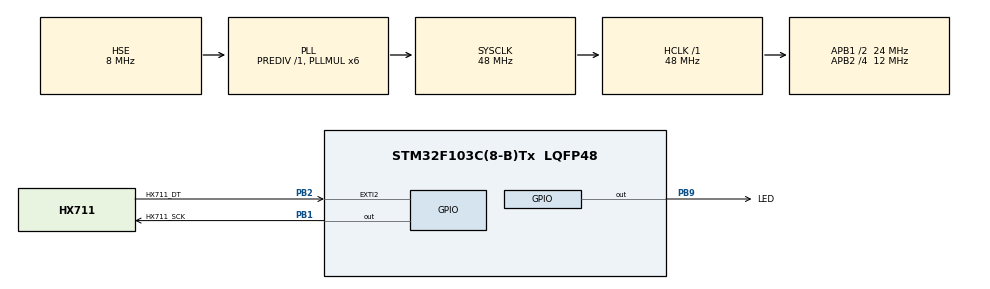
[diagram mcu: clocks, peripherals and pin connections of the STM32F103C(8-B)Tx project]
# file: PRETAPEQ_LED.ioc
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Mcu.Family=STM32F1
Mcu.Name=STM32F103C(8-B)Tx
Mcu.Package=LQFP48
NVIC.EXTI2_IRQn=true\:0\:0\:false\:false\:true\:true
NVIC.PriorityGroup=NVIC_PRIORITYGROUP_4
NVIC.TIM2_IRQn=true\:1\:0\:true\:false\:true\:true
PA13.Mode=Serial_Wire
PA13.Signal=SYS_JTMS-SWDIO
PA14.Mode=Serial_Wire
PA14.Signal=SYS_JTCK-SWCLK
PB1.GPIO_Label=HX711_SCK
PB1.GPIO_Speed=GPIO_SPEED_FREQ_HIGH
PB1.PinState=GPIO_PIN_SET
PB1.Signal=GPIO_Output
PB2.GPIO_Label=HX711_DT
PB2.GPIO_ModeDefaultEXTI=GPIO_MODE_IT_FALLING
PB2.GPIO_PuPd=GPIO_PULLDOWN
PB2.Signal=GPXTI2
PB9.GPIO_Label=LED
PB9.GPIO_Speed=GPIO_SPEED_FREQ_HIGH
PB9.PinState=GPIO_PIN_SET
PB9.Signal=GPIO_Output
PD0-OSC_IN.Mode=HSE-External-Oscillator
PD0-OSC_IN.Signal=RCC_OSC_IN
PD1-OSC_OUT.Mode=HSE-External-Oscillator
PD1-OSC_OUT.Signal=RCC_OSC_OUT
ProjectManager.HeapSize=0x200
ProjectManager.StackSize=0x400
ProjectManager.TargetToolchain=MDK-ARM V5
RCC.ADCPresc=RCC_ADCPCLK2_DIV6
RCC.AHBFreq_Value=48000000
RCC.APB1CLKDivider=RCC_HCLK_DIV2
RCC.APB1Freq_Value=24000000
RCC.APB1TimFreq_Value=48000000
RCC.APB2CLKDivider=RCC_HCLK_DIV4
RCC.APB2Freq_Value=12000000
RCC.APB2TimFreq_Value=24000000
RCC.HCLKFreq_Value=48000000
RCC.PLLMUL=RCC_PLL_MUL6
RCC.PLLSourceVirtual=RCC_PLLSOURCE_HSE
RCC.SYSCLKFreq_VALUE=48000000
RCC.SYSCLKSource=RCC_SYSCLKSOURCE_PLLCLK
RCC.USBFreq_Value=48000000
TIM2.Period=1000-1
TIM2.Prescaler=4800-1
VP_TIM2_VS_ClockSourceINT.Mode=Internal
board=custom

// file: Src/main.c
/**
  ******************************************************************************
  * @file           : main.c
  * @brief          : Main program body
  ******************************************************************************
  ** This notice applies to any and all portions of this file
  * that are not between comment pairs USER CODE BEGIN and
  * USER CODE END. Other portions of this file, whether
  * inserted by the user or by software development tools
  * are owned by their respective copyright owners.
  *
  * COPYRIGHT(c) 2019 STMicroelectronics
  *
  * Redistribution and use in source and binary forms, with or without modification,
  * are permitted provided that the following conditions are met:
  *   1. Redistributions of source code must retain the above copyright notice,
  *      this list of conditions and the following disclaimer.
  *   2. Redistributions in binary form must reproduce the above copyright notice,
  *      this list of conditions and the following disclaimer in the documentation
  *      and/or other materials provided with the distribution.
  *   3. Neither the name of STMicroelectronics nor the names of its contributors
  *      may be used to endorse or promote products derived from this software
  *      without specific prior written permission.
  *
  * THIS SOFTWARE IS PROVIDED BY THE COPYRIGHT HOLDERS AND CONTRIBUTORS "AS IS"
  * AND ANY EXPRESS OR IMPLIED WARRANTIES, INCLUDING, BUT NOT LIMITED TO, THE
  * IMPLIED WARRANTIES OF MERCHANTABILITY AND FITNESS FOR A PARTICULAR PURPOSE ARE
  * DISCLAIMED. IN NO EVENT SHALL THE COPYRIGHT HOLDER OR CONTRIBUTORS BE LIABLE
  * FOR ANY DIRECT, INDIRECT, INCIDENTAL, SPECIAL, EXEMPLARY, OR CONSEQUENTIAL
  * DAMAGES (INCLUDING, BUT NOT LIMITED TO, PROCUREMENT OF SUBSTITUTE GOODS OR
  * SERVICES; LOSS OF USE, DATA, OR PROFITS; OR BUSINESS INTERRUPTION) HOWEVER
  * CAUSED AND ON ANY THEORY OF LIABILITY, WHETHER IN CONTRACT, STRICT LIABILITY,
  * OR TORT (INCLUDING NEGLIGENCE OR OTHERWISE) ARISING IN ANY WAY OUT OF THE USE
  * OF THIS SOFTWARE, EVEN IF ADVISED OF THE POSSIBILITY OF SUCH DAMAGE.
  *
  ******************************************************************************
  */
#include "main.h"
#include "stm32f1xx_hal.h"

/* USER CODE BEGIN Includes */
#include "hx711.h"
#include "math.h"
/* USER CODE END Includes */

TIM_HandleTypeDef htim2;

/* USER CODE BEGIN PV */
/* Private variables ---------------------------------------------------------*/
int tim2_counter=0;

float avg=0;

int first_value=0;
int last_value=0;

extern int ad_value;
extern int adc;

int stable_counter=0;
int stable_flag=0;
int stable_value=0;

float fweight=0;
int weight=0;
int offset=0;

int EAS_offset=0;
int EAS_factor=0;
int EAS_value=0;

float factor=1;
//float factor=6.724;
//float factor=26.7886;

int offset_counter=0;

int countdown=30;

int w=0;
int v1=0;
int v2=0;
int ct=0;
int f=0;

int seg=0;
int avg_inf=0;
extern int inf;
/* USER CODE END PV */

void SystemClock_Config(void);
static void MX_GPIO_Init(void);
static void MX_TIM2_Init(void);

/* USER CODE BEGIN PFP */
/* Private function prototypes -----------------------------------------------*/

/* USER CODE END PFP */

int main(void)
{

  /* MCU Configuration----------------------------------------------------------*/

  /* Reset of all peripherals, Initializes the Flash interface and the Systick. */
  HAL_Init();

  /* Configure the system clock */
  SystemClock_Config();

  /* Initialize all configured peripherals */
  MX_GPIO_Init();
  MX_TIM2_Init();
  /* USER CODE BEGIN 2 */
	HAL_TIM_Base_Start_IT(&htim2);
	HAL_NVIC_DisableIRQ(EXTI2_IRQn);
	Init();
	HAL_NVIC_EnableIRQ(EXTI2_IRQn);
  /* USER CODE END 2 */

  /* Infinite loop */
  while (1)
  {

  /* USER CODE BEGIN 3 */
	HAL_Delay(10);
	//	HAL_Delay(25);

	first_value=ad_value;

	if (stable_flag == 0)
	{
		if (first_value >= last_value -10 && first_value <= last_value +10)		stable_counter++;
		else																																	stable_counter=0;

		if (stable_counter>=10){
				stable_value=ad_value;
				stable_flag=1;
		}
	}
	else
	{
		if (first_value < last_value -10 || first_value > last_value +10)	{
			stable_counter=0;
			stable_flag=0;
		}

		if (stable_value > ad_value +10 || stable_value < ad_value -10)				stable_value=ad_value;

		if (offset >= stable_value -20 && offset <= stable_value +20)					offset_counter++;
		else																																offset_counter=0;

		if (offset_counter>=10){
				stable_value=ad_value;
				offset=stable_value;
				offset_counter=0;
		}
	}

	last_value=first_value;

	if (EAS_offset){
		offset=stable_value;
		EAS_offset=0;
	}

	if (EAS_factor)
	{
		factor=(stable_value-offset)/(float)EAS_value;
		EAS_factor=0;
	}

	if (stable_flag)	weight=stable_value-offset;
	else							weight=stable_value-offset;

	fweight=(float)weight/factor;

	w = round(fweight);

  }
  /* USER CODE END 3 */

}

void SystemClock_Config(void)
{

  RCC_OscInitTypeDef RCC_OscInitStruct;
  RCC_ClkInitTypeDef RCC_ClkInitStruct;

    /**Initializes the CPU, AHB and APB busses clocks
    */
  RCC_OscInitStruct.OscillatorType = RCC_OSCILLATORTYPE_HSE;
  RCC_OscInitStruct.HSEState = RCC_HSE_ON;
  RCC_OscInitStruct.HSEPredivValue = RCC_HSE_PREDIV_DIV1;
  RCC_OscInitStruct.HSIState = RCC_HSI_ON;
  RCC_OscInitStruct.PLL.PLLState = RCC_PLL_ON;
  RCC_OscInitStruct.PLL.PLLSource = RCC_PLLSOURCE_HSE;
  RCC_OscInitStruct.PLL.PLLMUL = RCC_PLL_MUL6;
  if (HAL_RCC_OscConfig(&RCC_OscInitStruct) != HAL_OK)
  {
    _Error_Handler(__FILE__, __LINE__);
  }

    /**Initializes the CPU, AHB and APB busses clocks
    */
  RCC_ClkInitStruct.ClockType = RCC_CLOCKTYPE_HCLK|RCC_CLOCKTYPE_SYSCLK
                              |RCC_CLOCKTYPE_PCLK1|RCC_CLOCKTYPE_PCLK2;
  RCC_ClkInitStruct.SYSCLKSource = RCC_SYSCLKSOURCE_PLLCLK;
  RCC_ClkInitStruct.AHBCLKDivider = RCC_SYSCLK_DIV1;
  RCC_ClkInitStruct.APB1CLKDivider = RCC_HCLK_DIV2;
  RCC_ClkInitStruct.APB2CLKDivider = RCC_HCLK_DIV4;

  if (HAL_RCC_ClockConfig(&RCC_ClkInitStruct, FLASH_LATENCY_1) != HAL_OK)
  {
    _Error_Handler(__FILE__, __LINE__);
  }

    /**Configure the Systick interrupt time
    */
  HAL_SYSTICK_Config(HAL_RCC_GetHCLKFreq()/1000);

    /**Configure the Systick
    */
  HAL_SYSTICK_CLKSourceConfig(SYSTICK_CLKSOURCE_HCLK);

  /* SysTick_IRQn interrupt configuration */
  HAL_NVIC_SetPriority(SysTick_IRQn, 0, 0);
}

/* TIM2 init function */
static void MX_TIM2_Init(void)
{

  TIM_ClockConfigTypeDef sClockSourceConfig;
  TIM_MasterConfigTypeDef sMasterConfig;

  htim2.Instance = TIM2;
  htim2.Init.Prescaler = 4800-1;
  htim2.Init.CounterMode = TIM_COUNTERMODE_UP;
  htim2.Init.Period = 1000-1;
  htim2.Init.ClockDivision = TIM_CLOCKDIVISION_DIV1;
  htim2.Init.AutoReloadPreload = TIM_AUTORELOAD_PRELOAD_DISABLE;
  if (HAL_TIM_Base_Init(&htim2) != HAL_OK)
  {
    _Error_Handler(__FILE__, __LINE__);
  }

  sClockSourceConfig.ClockSource = TIM_CLOCKSOURCE_INTERNAL;
  if (HAL_TIM_ConfigClockSource(&htim2, &sClockSourceConfig) != HAL_OK)
  {
    _Error_Handler(__FILE__, __LINE__);
  }

  sMasterConfig.MasterOutputTrigger = TIM_TRGO_RESET;
  sMasterConfig.MasterSlaveMode = TIM_MASTERSLAVEMODE_DISABLE;
  if (HAL_TIMEx_MasterConfigSynchronization(&htim2, &sMasterConfig) != HAL_OK)
  {
    _Error_Handler(__FILE__, __LINE__);
  }

}

/** Configure pins as
        * Analog
        * Input
        * Output
        * EVENT_OUT
        * EXTI
*/
static void MX_GPIO_Init(void)
{

  GPIO_InitTypeDef GPIO_InitStruct;

  /* GPIO Ports Clock Enable */
  __HAL_RCC_GPIOD_CLK_ENABLE();
  __HAL_RCC_GPIOB_CLK_ENABLE();
  __HAL_RCC_GPIOA_CLK_ENABLE();

  /*Configure GPIO pin Output Level */
  HAL_GPIO_WritePin(GPIOB, HX711_SCK_Pin|LED_Pin, GPIO_PIN_SET);

  /*Configure GPIO pins : HX711_SCK_Pin LED_Pin */
  GPIO_InitStruct.Pin = HX711_SCK_Pin|LED_Pin;
  GPIO_InitStruct.Mode = GPIO_MODE_OUTPUT_PP;
  GPIO_InitStruct.Pull = GPIO_NOPULL;
  GPIO_InitStruct.Speed = GPIO_SPEED_FREQ_HIGH;
  HAL_GPIO_Init(GPIOB, &GPIO_InitStruct);

  /*Configure GPIO pin : HX711_DT_Pin */
  GPIO_InitStruct.Pin = HX711_DT_Pin;
  GPIO_InitStruct.Mode = GPIO_MODE_IT_FALLING;
  GPIO_InitStruct.Pull = GPIO_PULLDOWN;
  HAL_GPIO_Init(HX711_DT_GPIO_Port, &GPIO_InitStruct);

  /* EXTI interrupt init*/
  HAL_NVIC_SetPriority(EXTI2_IRQn, 0, 0);
  HAL_NVIC_EnableIRQ(EXTI2_IRQn);

}

/* USER CODE BEGIN 4 */
void HAL_TIM_PeriodElapsedCallback(TIM_HandleTypeDef *htim)
{
  if (htim->Instance == TIM2)
	{
//		if (seg<100)
//		{
//				//PutBuffer(ad_value,8);
//			PutBuffer(adc,100);
//				seg++;
//		}
//		else
//		{
//				avg=TakeAverage(100);
//			ad_value=round(avg);
//				avg_inf=inf;
//				inf=0;
//				seg=0;
//		}

		v1=w;

		if (v1==v2)
		{
			if (ct<10) ct++;
		}
		else
		{
			ct=0; //if (ct>0) ct--;
		}

		if (ct==10)	HAL_GPIO_WritePin(LED_GPIO_Port, LED_Pin, GPIO_PIN_RESET);
		else	HAL_GPIO_WritePin(LED_GPIO_Port, LED_Pin, GPIO_PIN_SET);

		v2=v1;

		if (countdown>0){
			if (countdown==1) EAS_offset=1;
			countdown--;
		}

//		if (tim2_counter<1)
//				tim2_counter++;
//		else
//		{
//				tim2_counter=0;
//				HAL_GPIO_TogglePin(LED_GPIO_Port,LED_Pin);
//		}

//		  tim2_counter < 10 ? (tim2_counter=tim2_counter+1) : (tim2_counter=0);
//			if (!tim2_counter)	HAL_GPIO_TogglePin(LED_GPIO_Port,LED_Pin);
  }
}
/* USER CODE END 4 */

void _Error_Handler(char *file, int line)
{
  while(1)
  {
  }
}

/************************ (C) COPYRIGHT STMicroelectronics *****END OF FILE****/
